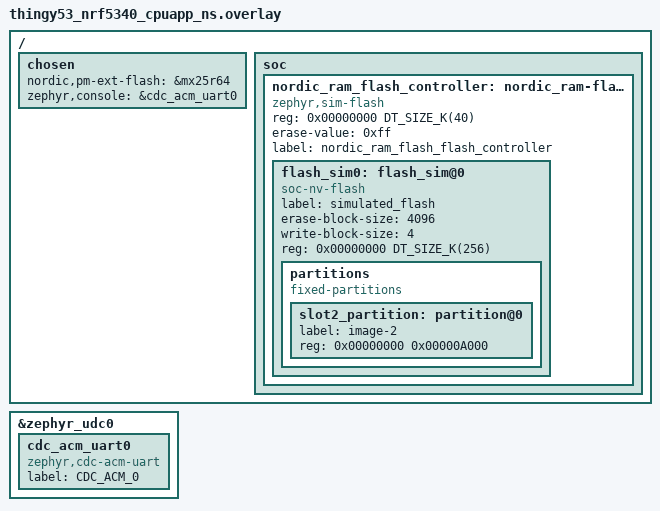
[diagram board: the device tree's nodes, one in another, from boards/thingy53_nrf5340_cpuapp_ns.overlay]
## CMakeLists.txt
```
#
# Copyright (c) 2020 Nordic Semiconductor ASA
#
# SPDX-License-Identifier: LicenseRef-Nordic-5-Clause
#
cmake_minimum_required(VERSION 3.20.0)

set(PM_STATIC_YML_FILE
  ${CMAKE_CURRENT_SOURCE_DIR}/boards/pm_static_${BOARD}.yml
  )

find_package(Zephyr REQUIRED HINTS $ENV{ZEPHYR_BASE})
project(NONE)

# NORDIC SDK APP START
target_sources(app PRIVATE
	src/main.c
	src/model_handler.c
	src/lc_pwm_led.c)
target_include_directories(app PRIVATE include)
# NORDIC SDK APP END

# Preinitialization related to Thingy:53 DFU
target_sources_ifdef(CONFIG_BOARD_THINGY53_NRF5340_CPUAPP app PRIVATE
  boards/thingy53.c
)
target_sources_ifdef(CONFIG_BOARD_THINGY53_NRF5340_CPUAPP_NS app PRIVATE
  boards/thingy53.c
)
```

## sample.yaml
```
sample:
  name: Bluetooth mesh light fixture
  description: Bluetooth mesh light fixture sample
tests:
  samples.bluetooth.mesh.light_ctrl:
    build_only: true
    platform_allow: nrf52dk_nrf52832 nrf52840dk_nrf52840 nrf5340dk_nrf5340_cpuapp
      nrf5340dk_nrf5340_cpuapp_ns thingy53_nrf5340_cpuapp thingy53_nrf5340_cpuapp_ns
      nrf21540dk_nrf52840
    tags: bluetooth ci_build
    integration_platforms:
      - nrf52dk_nrf52832
      - nrf52840dk_nrf52840
      - nrf5340dk_nrf5340_cpuapp
      - nrf5340dk_nrf5340_cpuapp_ns
      - thingy53_nrf5340_cpuapp
      - thingy53_nrf5340_cpuapp_ns
      - nrf21540dk_nrf52840
```

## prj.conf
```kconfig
#
# Copyright (c) 2020 Nordic Semiconductor ASA
#
# SPDX-License-Identifier: LicenseRef-Nordic-5-Clause
#
CONFIG_NCS_SAMPLES_DEFAULTS=y

# General configuration
CONFIG_SYSTEM_WORKQUEUE_STACK_SIZE=2048
CONFIG_FLASH=y
CONFIG_FLASH_MAP=y
CONFIG_NVS=y
CONFIG_SETTINGS=y
CONFIG_HWINFO=y
CONFIG_DK_LIBRARY=y
CONFIG_PWM=y

# Bluetooth configuration
CONFIG_BT=y
CONFIG_BT_COMPANY_ID=0x0059
CONFIG_BT_DEVICE_NAME="Mesh Light Fixture"
CONFIG_BT_L2CAP_TX_MTU=69
CONFIG_BT_L2CAP_TX_BUF_COUNT=8
CONFIG_BT_OBSERVER=y
CONFIG_BT_PERIPHERAL=y

# Disable unused Bluetooth features
CONFIG_BT_CTLR_DUP_FILTER_LEN=0
CONFIG_BT_CTLR_LE_ENC=n
CONFIG_BT_DATA_LEN_UPDATE=n
CONFIG_BT_PHY_UPDATE=n
CONFIG_BT_CTLR_CHAN_SEL_2=n
CONFIG_BT_CTLR_MIN_USED_CHAN=n
CONFIG_BT_CTLR_PRIVACY=n

# Bluetooth mesh configuration
CONFIG_BT_MESH=y
CONFIG_BT_MESH_RELAY=y
CONFIG_BT_MESH_FRIEND=y
CONFIG_BT_MESH_ADV_BUF_COUNT=13
CONFIG_BT_MESH_TX_SEG_MAX=10
CONFIG_BT_MESH_PB_GATT=y
CONFIG_BT_MESH_PROXY_USE_DEVICE_NAME=y
CONFIG_BT_MESH_GATT_PROXY=y
CONFIG_BT_MESH_DK_PROV=y

# Bluetooth mesh models
CONFIG_BT_MESH_LIGHT_CTRL_SRV=y
CONFIG_BT_MESH_LIGHT_CTRL_SRV_TIME_ON=3
CONFIG_BT_MESH_LIGHT_CTRL_SRV_TIME_PROLONG=3
CONFIG_BT_MESH_LIGHT_CTRL_SRV_RESUME_DELAY=30
```

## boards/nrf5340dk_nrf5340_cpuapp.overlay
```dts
&pwm0 {
	status = "okay";
	ch0-pin = <28>;
	ch0-inverted;
};
```

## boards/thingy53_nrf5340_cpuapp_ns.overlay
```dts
/*
 * Copyright (c) 2021 Nordic Semiconductor ASA
 *
 * SPDX-License-Identifier: LicenseRef-Nordic-5-Clause
 */

/ {
	chosen {
		nordic,pm-ext-flash = &mx25r64;
	};
};

/*
 * This file is used to enable a partition which is used through the flash API
 * but which is in reality stored in RAM. This is done to load data from
 * external flash to the network core. Since the network core cannot access
 * the external flash directly, the data is buffered in RAM before being
 * copied by the network core to the network core flash.
 *
 * The partition must be enabled by the application configuration to prevent
 * bus faults when mcumgr tries to access simulated partition with network core
 * image data.
 */

/ {
	soc {
		/* Add a flash controller which has the compatible
		 * 'zephyr,sim-flash'. This will ensure that the flash
		 * simulator can use it. None of the other properties in this
		 * node is used for anything.
		 */
		nordic_ram_flash_controller: nordic_ram-flash-controller@0 {
			compatible = "zephyr,sim-flash";
			reg = <0x00000000 DT_SIZE_K(40)>;
			#address-cells = <1>;
			#size-cells = <1>;
			erase-value = <0xff>;
			label = "nordic_ram_flash_flash_controller";

			/* This node label must match that used in the flash
			 * simulator.
			 */
			flash_sim0: flash_sim@0 {
				status = "okay";
				compatible = "soc-nv-flash";
				label = "simulated_flash";
				erase-block-size = <4096>;
				write-block-size = <4>;
				reg = <0x00000000 DT_SIZE_K(256)>;

				partitions {
					compatible = "fixed-partitions";
					#address-cells = <1>;
					#size-cells = <1>;

					/* This partition must be defined for
					 * MCUboot to find the partition ID
					 * of the primary slot for image 1,
					 * which is stored in this partition.
					 */
					slot2_partition: partition@0 {
						label = "image-2";
						reg = <0x00000000 0x00000A000>;
					};
				};
			};
		};
	};

	chosen {
		zephyr,console = &cdc_acm_uart0;
	};
};

&zephyr_udc0 {
	cdc_acm_uart0: cdc_acm_uart0 {
		compatible = "zephyr,cdc-acm-uart";
		label = "CDC_ACM_0";
	};
};
```

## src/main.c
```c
/*
 * Copyright (c) 2020 Nordic Semiconductor ASA
 *
 * SPDX-License-Identifier: LicenseRef-Nordic-5-Clause
 */

/** @file
 *  @brief Nordic mesh light fixture sample
 */
#include <bluetooth/bluetooth.h>
#include <bluetooth/mesh/models.h>
#include <bluetooth/mesh/dk_prov.h>
#include <dk_buttons_and_leds.h>
#include "model_handler.h"
#include "lc_pwm_led.h"

static void bt_ready(int err)
{
	if (err) {
		printk("Bluetooth init failed (err %d)\n", err);
		return;
	}

	printk("Bluetooth initialized\n");

	dk_leds_init();
	dk_buttons_init(NULL);

	err = bt_mesh_init(bt_mesh_dk_prov_init(), model_handler_init());
	if (err) {
		printk("Initializing mesh failed (err %d)\n", err);
		return;
	}

	if (IS_ENABLED(CONFIG_SETTINGS)) {
		settings_load();
	}

	/* This will be a no-op if settings_load() loaded provisioning info */
	bt_mesh_prov_enable(BT_MESH_PROV_ADV | BT_MESH_PROV_GATT);

	printk("Mesh initialized\n");

	model_handler_start();
}

void main(void)
{
	int err;

	printk("Initializing...\n");
	lc_pwm_led_init();
	err = bt_enable(bt_ready);
	if (err) {
		printk("Bluetooth init failed (err %d)\n", err);
	}
}
```

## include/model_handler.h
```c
/*
 * Copyright (c) 2020 Nordic Semiconductor ASA
 *
 * SPDX-License-Identifier: LicenseRef-Nordic-5-Clause
 */

/**
 * @file
 * @brief Model handler
 */

#ifndef MODEL_HANDLER_H__
#define MODEL_HANDLER_H__

#include <bluetooth/mesh.h>

#ifdef __cplusplus
extern "C" {
#endif

const struct bt_mesh_comp *model_handler_init(void);
void model_handler_start(void);

#ifdef __cplusplus
}
#endif

#endif /* MODEL_HANDLER_H__ */
```

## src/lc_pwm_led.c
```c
/*
 * Copyright (c) 2020 Nordic Semiconductor ASA
 *
 * SPDX-License-Identifier: LicenseRef-Nordic-5-Clause
 */

#include <bluetooth/mesh/models.h>
#include <dk_buttons_and_leds.h>
#include "model_handler.h"
#include <drivers/pwm.h>

#define PWM_LED0_NODE	DT_ALIAS(pwm_led0)

/*
 * Devicetree helper macro which gets the 'flags' cell from the node's
 * pwms property, or returns 0 if the property has no 'flags' cell.
 */

#if DT_PHA_HAS_CELL(PWM_LED0_NODE, pwms, flags)
#define PWM_FLAGS DT_PWMS_FLAGS(PWM_LED0_NODE)
#else
#define PWM_FLAGS 0
#endif

#if DT_NODE_HAS_STATUS(PWM_LED0_NODE, okay)
#define PWM_CTLR	DT_PWMS_CTLR(PWM_LED0_NODE)
#define PWM_CHANNEL	DT_PWMS_CHANNEL(PWM_LED0_NODE)
#else
#error "Unsupported board: pwm-led0 devicetree alias is not defined"
#define PWM_CTLR	DT_INVALID_NODE
#define PWM_CHANNEL	0
#endif

static const struct device *pwm;
#define PWM_PERIOD 1024

void lc_pwm_led_init(void)
{
	pwm = DEVICE_DT_GET(PWM_CTLR);
	if (!device_is_ready(pwm)) {
		printk("Error: PWM device %s is not ready\n", pwm->name);
		return;
	}
}

void lc_pwm_led_set(uint16_t desired_lvl)
{
	uint32_t scaled_lvl =
		(PWM_PERIOD * desired_lvl) /
		BT_MESH_LIGHTNESS_MAX;

	pwm_pin_set_usec(pwm,
		PWM_CHANNEL,
		PWM_PERIOD,
		scaled_lvl,
		PWM_FLAGS);
}
```

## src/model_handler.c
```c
/*
 * Copyright (c) 2020 Nordic Semiconductor ASA
 *
 * SPDX-License-Identifier: LicenseRef-Nordic-5-Clause
 */

#include <bluetooth/bluetooth.h>
#include <bluetooth/mesh/models.h>
#include <dk_buttons_and_leds.h>
#include "model_handler.h"
#include "lc_pwm_led.h"

#define PWM_SIZE_STEP 512

struct lightness_ctx {
	struct bt_mesh_lightness_srv lightness_srv;
	struct k_work_delayable per_work;
	uint16_t target_lvl;
	uint16_t current_lvl;
	uint32_t time_per;
	uint32_t rem_time;
};

/* Set up a repeating delayed work to blink the DK's LEDs when attention is
 * requested.
 */
static struct k_work_delayable attention_blink_work;
static bool attention;

static void attention_blink(struct k_work *work)
{
	static int idx;
	const uint8_t pattern[] = {
#if DT_NODE_EXISTS(DT_ALIAS(led0))
		BIT(0),
#endif
#if DT_NODE_EXISTS(DT_ALIAS(led1))
		BIT(1),
#endif
#if DT_NODE_EXISTS(DT_ALIAS(led2))
		BIT(2),
#endif
#if DT_NODE_EXISTS(DT_ALIAS(led3))
		BIT(3),
#endif
	};

	if (attention) {
		dk_set_leds(pattern[idx++ % ARRAY_SIZE(pattern)]);
		k_work_reschedule(&attention_blink_work, K_MSEC(30));
	} else {
		dk_set_leds(DK_NO_LEDS_MSK);
	}
}

static void attention_on(struct bt_mesh_model *mod)
{
	attention = true;
	k_work_reschedule(&attention_blink_work, K_NO_WAIT);
}

static void attention_off(struct bt_mesh_model *mod)
{
	/* Will stop rescheduling blink timer */
	attention = false;
}

static const struct bt_mesh_health_srv_cb health_srv_cb = {
	.attn_on = attention_on,
	.attn_off = attention_off,
};

static struct bt_mesh_health_srv health_srv = {
	.cb = &health_srv_cb,
};

BT_MESH_HEALTH_PUB_DEFINE(health_pub, 0);

static void start_new_light_trans(const struct bt_mesh_lightness_set *set,
				  struct lightness_ctx *ctx)
{
	uint32_t step_cnt = abs(set->lvl - ctx->current_lvl) / PWM_SIZE_STEP;
	uint32_t time = set->transition ? set->transition->time : 0;
	uint32_t delay = set->transition ? set->transition->delay : 0;

	ctx->target_lvl = set->lvl;
	ctx->time_per = (step_cnt ? time / step_cnt : 0);
	ctx->rem_time = time;
	k_work_reschedule(&ctx->per_work, K_MSEC(delay));

	printk("New light transition-> Lvl: %d, Time: %d, Delay: %d\n",
	       set->lvl, time, delay);
}

static void periodic_led_work(struct k_work *work)
{
	struct lightness_ctx *l_ctx =
		CONTAINER_OF(work, struct lightness_ctx, per_work);
	l_ctx->rem_time -= l_ctx->time_per;

	if ((l_ctx->rem_time <= l_ctx->time_per) ||
	    (abs(l_ctx->target_lvl - l_ctx->current_lvl) <= PWM_SIZE_STEP)) {
		struct bt_mesh_lightness_status status = {
			.current = l_ctx->target_lvl,
			.target = l_ctx->target_lvl,
		};

		l_ctx->current_lvl = l_ctx->target_lvl;
		l_ctx->rem_time = 0;

		bt_mesh_lightness_srv_pub(&l_ctx->lightness_srv, NULL, &status);

		goto apply_and_print;
	} else if (l_ctx->target_lvl > l_ctx->current_lvl) {
		l_ctx->current_lvl += PWM_SIZE_STEP;
	} else {
		l_ctx->current_lvl -= PWM_SIZE_STEP;
	}

	k_work_reschedule(&l_ctx->per_work, K_MSEC(l_ctx->time_per));
apply_and_print:
	lc_pwm_led_set(l_ctx->current_lvl);
	printk("Current light lvl: %u/65535\n", l_ctx->current_lvl);
}

static void light_set(struct bt_mesh_lightness_srv *srv,
		      struct bt_mesh_msg_ctx *ctx,
		      const struct bt_mesh_lightness_set *set,
		      struct bt_mesh_lightness_status *rsp)
{
	struct lightness_ctx *l_ctx =
		CONTAINER_OF(srv, struct lightness_ctx, lightness_srv);

	start_new_light_trans(set, l_ctx);
	rsp->current = l_ctx->current_lvl;
	rsp->target = l_ctx->target_lvl;
	rsp->remaining_time = set->transition ? set->transition->time : 0;
}

static void light_get(struct bt_mesh_lightness_srv *srv,
		      struct bt_mesh_msg_ctx *ctx,
		      struct bt_mesh_lightness_status *rsp)
{
	struct lightness_ctx *l_ctx =
		CONTAINER_OF(srv, struct lightness_ctx, lightness_srv);

	rsp->current = l_ctx->current_lvl;
	rsp->target = l_ctx->target_lvl;
	rsp->remaining_time = l_ctx->rem_time;
}

static const struct bt_mesh_lightness_srv_handlers lightness_srv_handlers = {
	.light_set = light_set,
	.light_get = light_get,
};

static struct lightness_ctx my_ctx = {
	.lightness_srv = BT_MESH_LIGHTNESS_SRV_INIT(&lightness_srv_handlers),

};

static struct bt_mesh_light_ctrl_srv light_ctrl_srv =
	BT_MESH_LIGHT_CTRL_SRV_INIT(&my_ctx.lightness_srv);

static struct bt_mesh_elem elements[] = {
	BT_MESH_ELEM(1,
		     BT_MESH_MODEL_LIST(
			     BT_MESH_MODEL_CFG_SRV,
			     BT_MESH_MODEL_HEALTH_SRV(&health_srv, &health_pub),
			     BT_MESH_MODEL_LIGHTNESS_SRV(
					 &my_ctx.lightness_srv)),
		     BT_MESH_MODEL_NONE),
	BT_MESH_ELEM(2,
		     BT_MESH_MODEL_LIST(
			     BT_MESH_MODEL_LIGHT_CTRL_SRV(&light_ctrl_srv)),
		     BT_MESH_MODEL_NONE),
};

static const struct bt_mesh_comp comp = {
	.cid = CONFIG_BT_COMPANY_ID,
	.elem = elements,
	.elem_count = ARRAY_SIZE(elements),
};

const struct bt_mesh_comp *model_handler_init(void)
{
	k_work_init_delayable(&attention_blink_work, attention_blink);
	k_work_init_delayable(&my_ctx.per_work, periodic_led_work);

	return &comp;
}

void model_handler_start(void)
{
	int err;

	if (bt_mesh_is_provisioned()) {
		return;
	}

	err = bt_mesh_light_ctrl_srv_enable(&light_ctrl_srv);
	if (!err) {
		printk("Successfully enabled LC server\n");
	}
}
```
